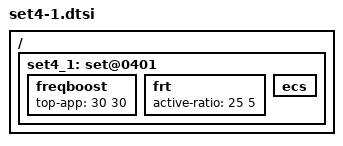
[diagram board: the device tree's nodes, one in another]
/ {
	/* balance mode - touch boost */
	set4_1: set@0401{
		/* Boosting margin applied to frequency selection */
		freqboost {	   		/* LIT BIG */
			top-app         	= < 30  30>;
		};

		frt {	   			/* LIT BIG */
			active-ratio 		= < 25   5>;
		};

		ecs { };
	};
};
